VERSION ""

NS_ :

BS_:

BU_: EON SMART PED
VAL_TABLE_ BRAKEMODE 3 "Reserved" 2 "Position Control" 1 "Relative Control" 0 "Disengadged" ;
VAL_TABLE_ STATUS 5 "FAULT_TIMEOUT" 4 "FAULT_STARTUP" 3 "FAULT_SCE" 2 "FAULT_SEND" 1 "FAULT_BAD_CHECKSUM" 0 "NO_FAULT" ;
VAL_TABLE_ STEERINGMODE 3 "Reserved" 2 "Position Control" 1 "Torque Control" 0 "Disengadged" ;
VAL_TABLE_ YESNO 1 "Yes" 0 "No" ;

BO_ 1585 SMART_ROADSTER_MESSAGE8: 8 SMART

BO_ 1301 SMART_ROADSTER_MESSAGE7: 7 SMART

BO_ 816 SMART_ROADSTER_MESSAGE6: 2 SMART

BO_ 768 SMART_ROADSTER_MESSAGE5: 8 SMART

BO_ 570 SMART_ROADSTER_MESSAGE4: 8 SMART

BO_ 568 SMART_ROADSTER_MESSAGE3: 8 SMART

BO_ 528 SMART_MEG_02: 8 SMART
 SG_ MANIFOLDPRESSURE : 24|8@1+ (0.01,-0.9) [0|5] "bar" EON

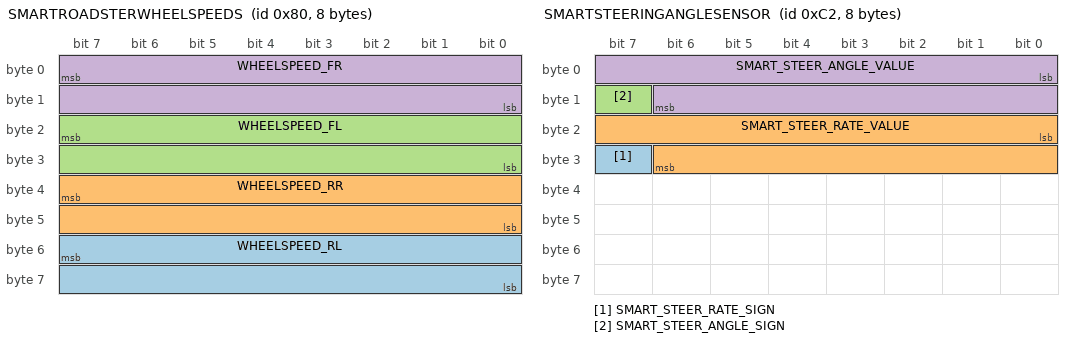
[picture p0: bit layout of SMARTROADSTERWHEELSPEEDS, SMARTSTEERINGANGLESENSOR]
BO_ 128 SMARTROADSTERWHEELSPEEDS: 8 SMART
 SG_ WHEELSPEED_RL : 55|16@0+ (0.034,0) [0|65535] "mph" EON
 SG_ WHEELSPEED_RR : 39|16@0+ (0.034,0) [0|65535] "mph" EON
 SG_ WHEELSPEED_FL : 23|16@0+ (0.034,0) [0|65535] "mph" EON
 SG_ WHEELSPEED_FR : 7|16@0+ (0.034,0) [0|65535] "mph" EON

BO_ 194 SMARTSTEERINGANGLESENSOR: 8 SMART
 SG_ SMART_STEER_RATE_SIGN : 31|1@1+ (1,0) [0|0] "" EON
 SG_ SMART_STEER_RATE_VALUE : 16|15@1+ (0.04375,0) [0|1433.6] "Deg/S" EON
 SG_ SMART_STEER_ANGLE_SIGN : 15|1@1+ (1,0) [0|0] "" EON
 SG_ SMART_STEER_ANGLE_VALUE : 0|15@1+ (0.04375,0) [0|1433.6] "Deg" EON

BO_ 784 SMARTTHROTTLEPEDAL: 8 SMART
 SG_ THROTTLE_POSITION : 32|16@1+ (0.00156143,0) [0|0] "%" EON

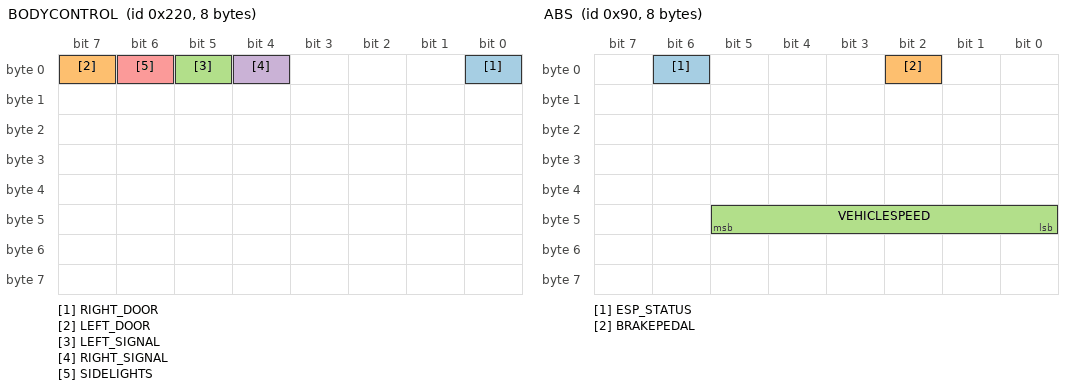
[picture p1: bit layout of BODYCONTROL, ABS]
BO_ 544 BODYCONTROL: 8 SMART
 SG_ RIGHT_DOOR : 0|1@1+ (1,0) [0|0] "" EON
 SG_ LEFT_DOOR : 7|1@1+ (1,0) [0|0] "" EON
 SG_ LEFT_SIGNAL : 5|1@1+ (1,0) [0|0] "" EON
 SG_ RIGHT_SIGNAL : 4|1@1+ (1,0) [0|0] "" EON
 SG_ SIDELIGHTS : 6|1@1+ (1,0) [0|0] "" EON

BO_ 144 ABS: 8 SMART
 SG_ ESP_STATUS : 6|1@1+ (1,0) [0|0] "" EON
 SG_ BRAKEPEDAL : 2|1@1+ (1,0) [0|0] "" EON
 SG_ VEHICLESPEED : 45|6@0- (1,0) [0|0] "mph" EON

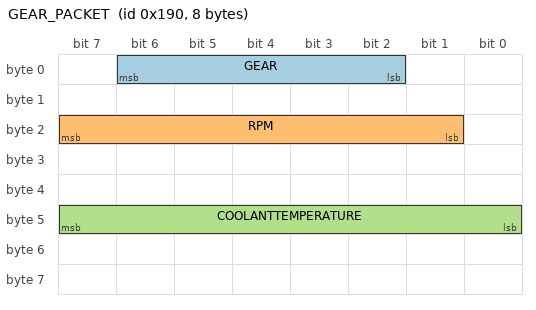
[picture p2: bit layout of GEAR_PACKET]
BO_ 400 GEAR_PACKET: 8 SMART
 SG_ GEAR : 2|5@1+ (1,0) [0|0] "" EON
 SG_ RPM : 23|7@0+ (50,0) [0|0] "" EON
 SG_ COOLANTTEMPERATURE : 40|8@1+ (1,-40) [-40|215] "C" EON

BO_ 520 SMART_ROADSTER_MESSAGE1: 8 SMART

CM_ SG_ 741 CHECKSUM "CRC8_J1650 SAE Checksum";
CM_ SG_ 608 CHECKSUM "CRC8_J1650 SAE Checksum";
BA_DEF_ BO_  "GenMsgBackgroundColor" STRING ;
BA_DEF_ BO_  "GenMsgForegroundColor" STRING ;
BA_DEF_DEF_  "GenMsgBackgroundColor" "#1e1e1e";
BA_DEF_DEF_  "GenMsgForegroundColor" "#ffffff";

VAL_ 544 RIGHT_DOOR 0 "Open" 1 "Closed" ;
VAL_ 544 LEFT_DOOR 0 "Open" 1 "Closed" ;
VAL_ 544 LEFT_SIGNAL 0 "Off" 1 "On" ;
VAL_ 544 RIGHT_SIGNAL 0 "Off" 1 "On" ;
VAL_ 544 SIDELIGHTS 0 "Off" 1 "On" ;
VAL_ 144 ESP_STATUS 0 "On" 1 "Off" ;
VAL_ 144 BRAKEPEDAL 0 "Not_pressed" 1 "Pressed" ;
VAL_ 400 GEAR 0 "P" 2 "N" 1 "R" 19 "D" 3 "S" ;
